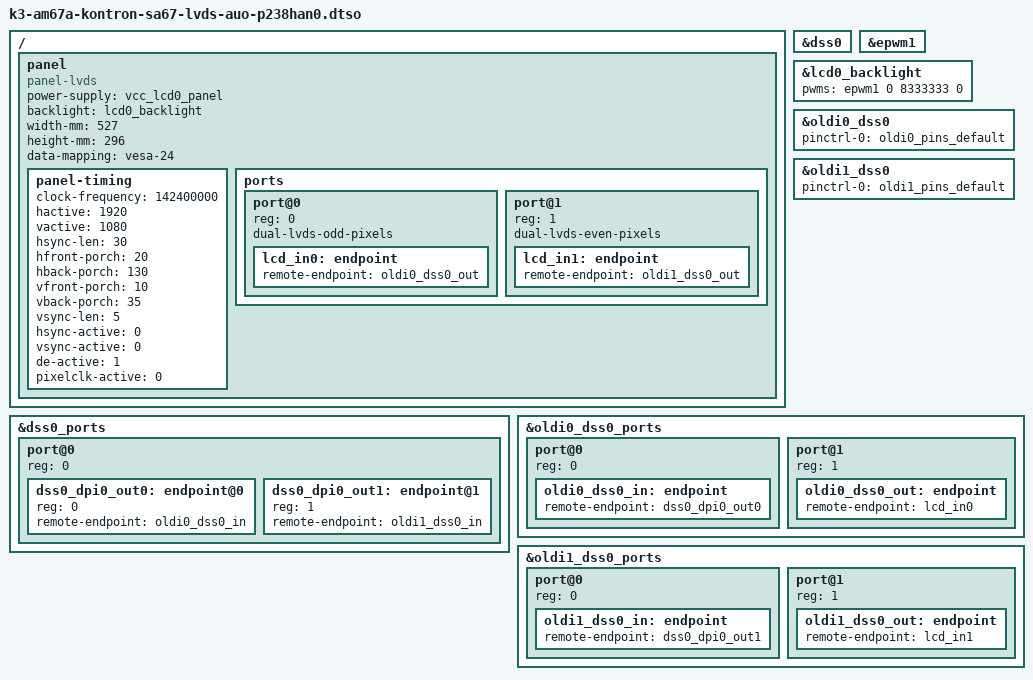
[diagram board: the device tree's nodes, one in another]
/dts-v1/;
/plugin/;

/ {
	panel {
		compatible = "panel-lvds";
		power-supply = <&vcc_lcd0_panel>;
		backlight = <&lcd0_backlight>;

		width-mm = <527>;
		height-mm = <296>;
		data-mapping = "vesa-24";
		status = "okay";

		panel-timing {
			clock-frequency = <142400000>;
			hactive = <1920>;
			vactive = <1080>;
			hsync-len = <30>;
			hfront-porch = <20>;
			hback-porch = <130>;
			vfront-porch = <10>;
			vback-porch = <35>;
			vsync-len = <5>;
			hsync-active = <0>;
			vsync-active = <0>;
			de-active = <1>;
			pixelclk-active = <0>;
		};

		/*
		* Note that the OLDI TX 0 transmits the odd set of pixels
		* while the OLDI TX 1 transmits the even set. This is a
		* fixed configuration in the IP integration and is not
		* changeable. The properties, "dual-lvds-odd-pixels" and
		* "dual-lvds-even-pixels" have been used to merely
		* identify if a Dual Link configuration is required.
		* Swapping them will cause an error in the dss oldi driver.
		*/
		ports {
			#address-cells = <1>;
			#size-cells = <0>;

			port@0 {
				reg = <0>;
				dual-lvds-odd-pixels;

				lcd_in0: endpoint {
					remote-endpoint = <&oldi0_dss0_out>;
				};
			};
			port@1 {
				reg = <1>;
				dual-lvds-even-pixels;

				lcd_in1: endpoint {
					remote-endpoint = <&oldi1_dss0_out>;
				};
			};
		};
	};
};

&dss0 {
	status = "okay";
};

&dss0_ports {
	#address-cells = <1>;
	#size-cells = <0>;

	/* VP1: Output to OLDI */
	port@0 {
		reg = <0>;
		#address-cells = <1>;
		#size-cells = <0>;

		dss0_dpi0_out0: endpoint@0 {
			reg = <0>;
			remote-endpoint = <&oldi0_dss0_in>;
		};

		dss0_dpi0_out1: endpoint@1 {
			reg = <1>;
			remote-endpoint = <&oldi1_dss0_in>;
		};
	};
};

&epwm1 {
	status = "okay";
};

&lcd0_backlight {
	pwms = <&epwm1 0 8333333 0>;
	status = "okay";
};

&oldi0_dss0 {
	pinctrl-names = "default";
	pinctrl-0 = <&oldi0_pins_default>;
	status = "okay";
};

&oldi1_dss0 {
	pinctrl-names = "default";
	pinctrl-0 = <&oldi1_pins_default>;
	status = "okay";
};

&oldi0_dss0_ports {
	#address-cells = <1>;
	#size-cells = <0>;

	port@0 {
		reg = <0>;

		oldi0_dss0_in: endpoint {
			remote-endpoint = <&dss0_dpi0_out0>;
		};
	};

	port@1 {
		reg = <1>;

		oldi0_dss0_out: endpoint {
			remote-endpoint = <&lcd_in0>;
		};
	};
};

&oldi1_dss0_ports {
	#address-cells = <1>;
	#size-cells = <0>;

	port@0 {
		reg = <0>;

		oldi1_dss0_in: endpoint {
			remote-endpoint = <&dss0_dpi0_out1>;
		};
	};

	port@1 {
		reg = <1>;

		oldi1_dss0_out: endpoint {
			remote-endpoint = <&lcd_in1>;
		};
	};
};
